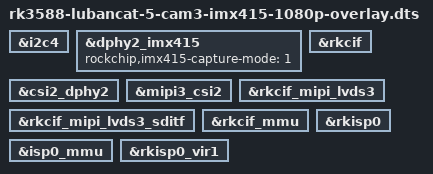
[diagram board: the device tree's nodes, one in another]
/dts-v1/;
/plugin/;

#include <dt-bindings/usb/pd.h>
#include <dt-bindings/gpio/gpio.h>
#include <dt-bindings/pwm/pwm.h>
#include <dt-bindings/pinctrl/rockchip.h>
#include <dt-bindings/input/rk-input.h>
#include <dt-bindings/display/drm_mipi_dsi.h>
#include <dt-bindings/display/rockchip_vop.h>
#include <dt-bindings/sensor-dev.h>

/ {
/* Link path: sensor->csi2_dphy1->mipi2_csi2->rkcif_mipi_lvds2--->rkcif_mipi_lvds2_sditf->rkisp0_vir2 */
	fragment@0 {
		target = <&i2c4>;
		__overlay__ {
			status = "okay";
		};
	};

	fragment@1 {
		target = <&dphy2_imx415>;
		__overlay__ {
			status = "okay";
			rockchip,imx415-capture-mode=<1>;
		};
	};

	fragment@3 {
		target = <&csi2_dphy2>;

		__overlay__ {
			status = "okay";
		};
	};

	fragment@4 {
		target = <&mipi3_csi2>;

		__overlay__ {
			status = "okay";
		};
	};

	fragment@5 {
		target = <&rkcif>;

		__overlay__ {
			status = "okay";
		};
	};

	fragment@6 {
		target = <&rkcif_mipi_lvds3>;

		__overlay__ {
			status = "okay";
		};
	};

	fragment@7 {
		target = <&rkcif_mipi_lvds3_sditf>;

		__overlay__ {
			status = "okay";
		};
	};

	fragment@8 {
		target = <&rkcif_mmu>;

		__overlay__ {
			status = "okay";
		};
	};

	fragment@9 {
		target = <&rkisp0>;

		__overlay__ {
			status = "okay";
		};
	};

	fragment@10 {
		target = <&isp0_mmu>;

		__overlay__ {
			status = "okay";
		};
	};

	fragment@11 {
		target = <&rkisp0_vir1>;

		__overlay__ {
			status = "okay";
		};
	};

};

